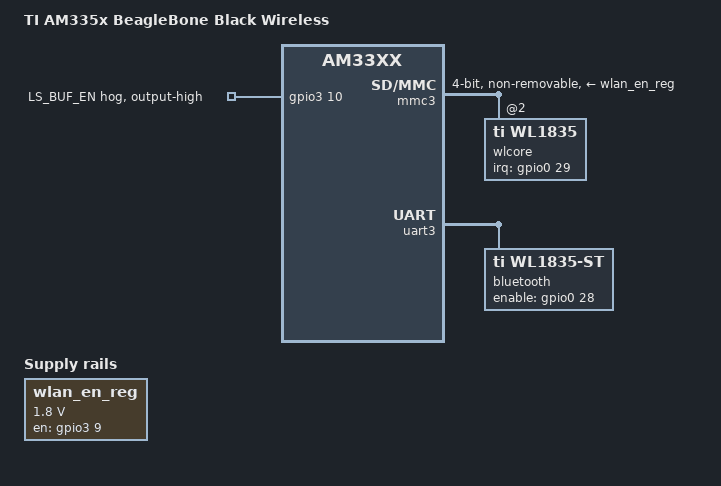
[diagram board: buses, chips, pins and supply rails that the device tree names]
/dts-v1/;
#include "am33xx.dtsi"
#include "am335x-bone-common.dtsi"
#include "am335x-boneblack-common.dtsi"
#include "am335x-boneblack-hdmi.dtsi"
#include <dt-bindings/interrupt-controller/irq.h>
/ {
	model = "TI AM335x BeagleBone Black Wireless";
	compatible = "ti,am335x-bone-black-wireless", "ti,am335x-bone-black", "ti,am335x-bone", "ti,am33xx";
	wlan_en_reg: fixedregulator@2 {
		compatible = "regulator-fixed";
		regulator-name = "wlan-en-regulator";
		regulator-min-microvolt = <1800000>;
		regulator-max-microvolt = <1800000>;
		startup-delay-us = <70000>;
		gpio = <&gpio3 9 0>;
		enable-active-high;
	};
};
&am33xx_pinmux {
	bt_pins: bt-pins {
		pinctrl-single,pins = <
			AM33XX_PADCONF(AM335X_PIN_MII1_TXD0, PIN_OUTPUT_PULLUP, MUX_MODE7)	 
		>;
	};
	mmc3_pins: mmc3-pins {
		pinctrl-single,pins = <
			AM33XX_PADCONF(AM335X_PIN_MII1_RXD1, PIN_INPUT_PULLUP, MUX_MODE6 )  
			AM33XX_PADCONF(AM335X_PIN_MII1_TX_EN, PIN_INPUT_PULLUP, MUX_MODE6 )  
			AM33XX_PADCONF(AM335X_PIN_MII1_RX_DV, PIN_INPUT_PULLUP, MUX_MODE5 )  
			AM33XX_PADCONF(AM335X_PIN_MII1_TXD3, PIN_INPUT_PULLUP, MUX_MODE5 )  
			AM33XX_PADCONF(AM335X_PIN_MII1_TXD2, PIN_INPUT_PULLUP, MUX_MODE5 )  
			AM33XX_PADCONF(AM335X_PIN_MII1_COL, PIN_INPUT_PULLUP, MUX_MODE5 )  
		>;
	};
	uart3_pins: uart3-pins {
		pinctrl-single,pins = <
			AM33XX_PADCONF(AM335X_PIN_MII1_RXD3, PIN_INPUT_PULLUP, MUX_MODE1)	 
			AM33XX_PADCONF(AM335X_PIN_MII1_RXD2, PIN_OUTPUT_PULLDOWN, MUX_MODE1)	 
			AM33XX_PADCONF(AM335X_PIN_MDIO, PIN_INPUT, MUX_MODE3)		 
			AM33XX_PADCONF(AM335X_PIN_MDC, PIN_OUTPUT_PULLDOWN, MUX_MODE3)	 
		>;
	};
	wl18xx_pins: wl18xx-pins {
		pinctrl-single,pins = <
			AM33XX_PADCONF(AM335X_PIN_MII1_TX_CLK, PIN_OUTPUT_PULLDOWN, MUX_MODE7)	 
			AM33XX_PADCONF(AM335X_PIN_RMII1_REF_CLK, PIN_INPUT_PULLDOWN, MUX_MODE7)	 
			AM33XX_PADCONF(AM335X_PIN_MII1_RX_CLK, PIN_OUTPUT_PULLUP, MUX_MODE7)	 
		>;
	};
};
&mac_sw {
	status = "disabled";
};
&mmc3 {
	dmas = <&edma_xbar 12 0 1
		&edma_xbar 13 0 2>;
	dma-names = "tx", "rx";
	status = "okay";
	vmmc-supply = <&wlan_en_reg>;
	bus-width = <4>;
	non-removable;
	cap-power-off-card;
	keep-power-in-suspend;
	pinctrl-names = "default";
	pinctrl-0 = <&mmc3_pins &wl18xx_pins>;
	#address-cells = <1>;
	#size-cells = <0>;
	wlcore: wlcore@2 {
		compatible = "ti,wl1835";
		reg = <2>;
		interrupt-parent = <&gpio0>;
		interrupts = <29 IRQ_TYPE_EDGE_RISING>;
	};
};
&uart3 {
	pinctrl-names = "default";
	pinctrl-0 = <&uart3_pins &bt_pins>;
	status = "okay";
	bluetooth {
		compatible = "ti,wl1835-st";
		enable-gpios = <&gpio0 28 GPIO_ACTIVE_HIGH>;
	};
};
&gpio3 {
	ls-buf-en-hog {
		gpio-hog;
		gpios = <10 GPIO_ACTIVE_HIGH>;
		output-high;
		line-name = "LS_BUF_EN";
	};
};
